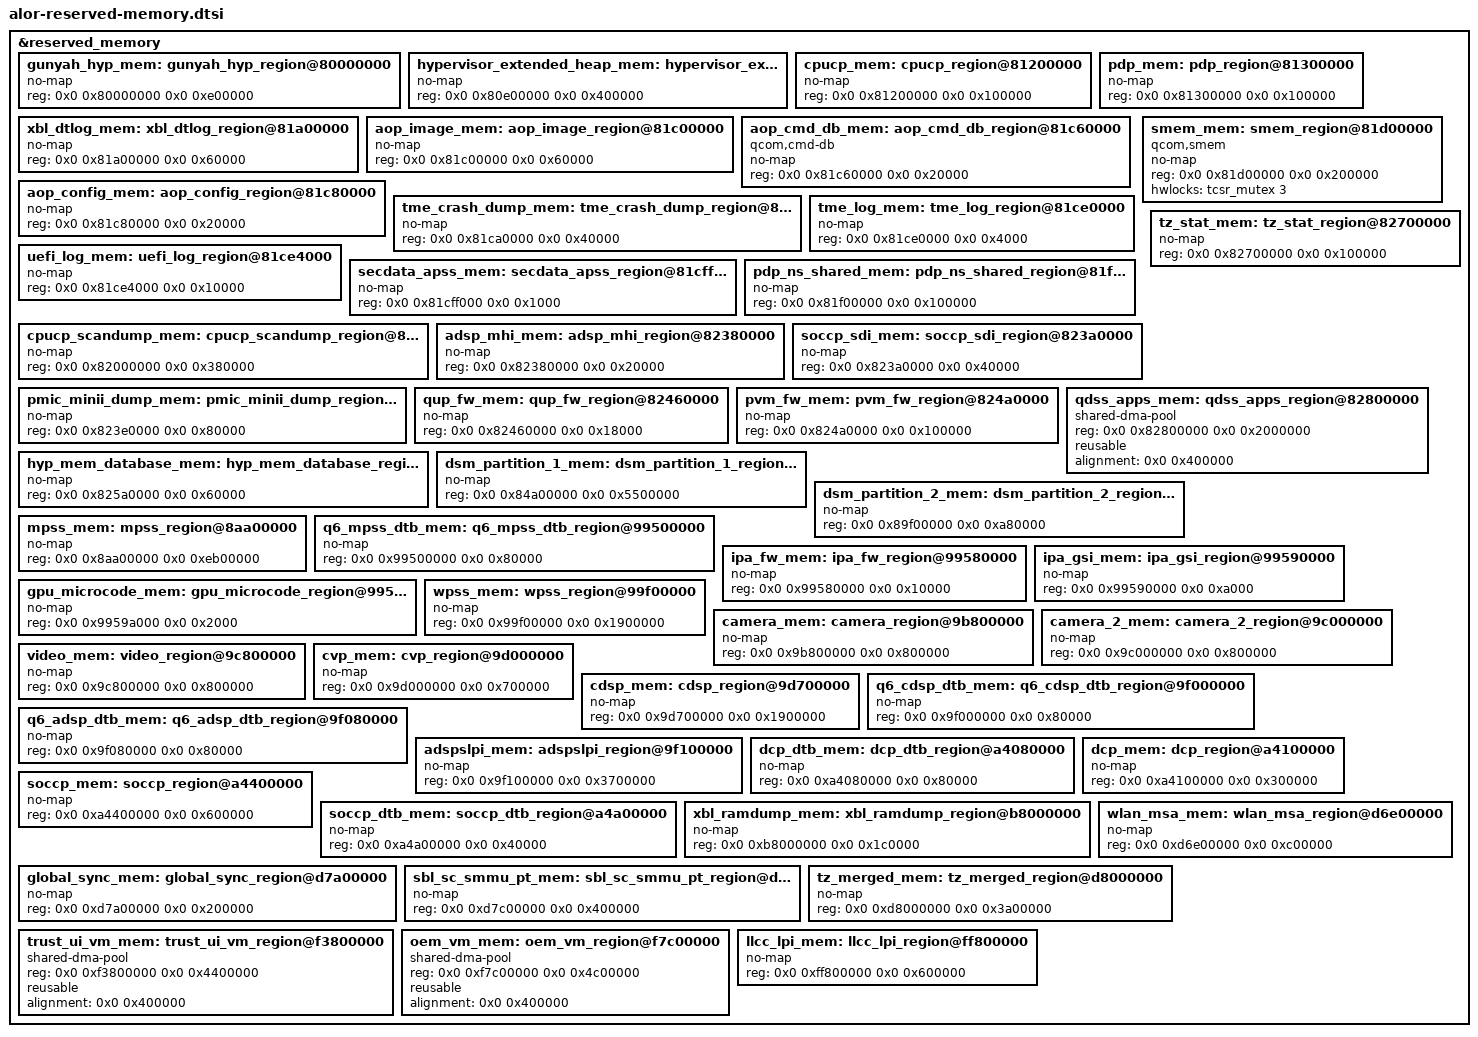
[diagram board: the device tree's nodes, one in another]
// SPDX-License-Identifier: BSD-3-Clause
/*
 * Copyright (c) Qualcomm Technologies, Inc. and/or its subsidiaries.
 */

&reserved_memory {
	#address-cells = <2>;
	#size-cells = <2>;
	ranges;

	gunyah_hyp_mem: gunyah_hyp_region@80000000 {
		no-map;
		reg = <0x0 0x80000000 0x0 0xe00000>;
	};

	hypervisor_extended_heap_mem: hypervisor_extended_heap_region@80e00000 {
		no-map;
		reg = <0x0 0x80e00000 0x0 0x400000>;
	};

	cpucp_mem: cpucp_region@81200000 {
		no-map;
		reg = <0x0 0x81200000 0x0 0x100000>;
	};

	pdp_mem: pdp_region@81300000 {
		no-map;
		reg = <0x0 0x81300000 0x0 0x100000>;
	};

	/*
	 * hyp_tags_mem is dynamically removed from the RAM
	 * partition tables before boot occurs. Size of region
	 * varies.
	 */

	xbl_dtlog_mem: xbl_dtlog_region@81a00000 {
		no-map;
		reg = <0x0 0x81a00000 0x0 0x60000>;
	};

	aop_image_mem: aop_image_region@81c00000 {
		no-map;
		reg = <0x0 0x81c00000 0x0 0x60000>;
	};

	aop_cmd_db_mem: aop_cmd_db_region@81c60000 {
		compatible = "qcom,cmd-db";
		no-map;
		reg = <0x0 0x81c60000 0x0 0x20000>;
	};

	aop_config_mem: aop_config_region@81c80000 {
		no-map;
		reg = <0x0 0x81c80000 0x0 0x20000>;
	};

	tme_crash_dump_mem: tme_crash_dump_region@81ca0000 {
		no-map;
		reg = <0x0 0x81ca0000 0x0 0x40000>;
	};

	tme_log_mem: tme_log_region@81ce0000 {
		no-map;
		reg = <0x0 0x81ce0000 0x0 0x4000>;
	};

	uefi_log_mem: uefi_log_region@81ce4000 {
		no-map;
		reg = <0x0 0x81ce4000 0x0 0x10000>;
	};

	secdata_apss_mem: secdata_apss_region@81cff000 {
		no-map;
		reg = <0x0 0x81cff000 0x0 0x1000>;
	};

	smem_mem: smem_region@81d00000 {
		compatible = "qcom,smem";
		no-map;
		reg = <0x0 0x81d00000 0x0 0x200000>;
		hwlocks = <&tcsr_mutex 3>;
	};

	pdp_ns_shared_mem: pdp_ns_shared_region@81f00000 {
		no-map;
		reg = <0x0 0x81f00000 0x0 0x100000>;
	};

	cpucp_scandump_mem: cpucp_scandump_region@82000000 {
		no-map;
		reg = <0x0 0x82000000 0x0 0x380000>;
	};

	adsp_mhi_mem: adsp_mhi_region@82380000 {
		no-map;
		reg = <0x0 0x82380000 0x0 0x20000>;
	};

	soccp_sdi_mem: soccp_sdi_region@823a0000 {
		no-map;
		reg = <0x0 0x823a0000 0x0 0x40000>;
	};

	pmic_minii_dump_mem: pmic_minii_dump_region@823e0000 {
		no-map;
		reg = <0x0 0x823e0000 0x0 0x80000>;
	};

	qup_fw_mem: qup_fw_region@82460000 {
		no-map;
		reg = <0x0 0x82460000 0x0 0x18000>;
	};

	pvm_fw_mem: pvm_fw_region@824a0000 {
		no-map;
		reg = <0x0 0x824a0000 0x0 0x100000>;
	};

	hyp_mem_database_mem: hyp_mem_database_region@825a0000 {
		no-map;
		reg = <0x0 0x825a0000 0x0 0x60000>;
	};

	tz_stat_mem: tz_stat_region@82700000 {
		no-map;
		reg = <0x0 0x82700000 0x0 0x100000>;
	};

	qdss_apps_mem: qdss_apps_region@82800000 {
		compatible = "shared-dma-pool";
		reg = <0x0 0x82800000 0x0 0x2000000>;
		reusable;
		alignment = <0x0 0x400000>;
	};

	dsm_partition_1_mem: dsm_partition_1_region@84a00000 {
		no-map;
		reg = <0x0 0x84a00000 0x0 0x5500000>;
	};

	dsm_partition_2_mem: dsm_partition_2_region@89f00000 {
		no-map;
		reg = <0x0 0x89f00000 0x0 0xa80000>;
	};

	mpss_mem: mpss_region@8aa00000 {
		no-map;
		reg = <0x0 0x8aa00000 0x0 0xeb00000>;
	};

	q6_mpss_dtb_mem: q6_mpss_dtb_region@99500000 {
		no-map;
		reg = <0x0 0x99500000 0x0 0x80000>;
	};

	ipa_fw_mem: ipa_fw_region@99580000 {
		no-map;
		reg = <0x0 0x99580000 0x0 0x10000>;
	};

	ipa_gsi_mem: ipa_gsi_region@99590000 {
		no-map;
		reg = <0x0 0x99590000 0x0 0xa000>;
	};

	gpu_microcode_mem: gpu_microcode_region@9959a000 {
		no-map;
		reg = <0x0 0x9959a000 0x0 0x2000>;
	};

	wpss_mem: wpss_region@99f00000 {
		no-map;
		reg = <0x0 0x99f00000 0x0 0x1900000>;
	};

	camera_mem: camera_region@9b800000 {
		no-map;
		reg = <0x0 0x9b800000 0x0 0x800000>;
	};

	camera_2_mem: camera_2_region@9c000000 {
		no-map;
		reg = <0x0 0x9c000000 0x0 0x800000>;
	};

	video_mem: video_region@9c800000 {
		no-map;
		reg = <0x0 0x9c800000 0x0 0x800000>;
	};

	cvp_mem: cvp_region@9d000000 {
		no-map;
		reg = <0x0 0x9d000000 0x0 0x700000>;
	};

	cdsp_mem: cdsp_region@9d700000 {
		no-map;
		reg = <0x0 0x9d700000 0x0 0x1900000>;
	};

	q6_cdsp_dtb_mem: q6_cdsp_dtb_region@9f000000 {
		no-map;
		reg = <0x0 0x9f000000 0x0 0x80000>;
	};

	q6_adsp_dtb_mem: q6_adsp_dtb_region@9f080000 {
		no-map;
		reg = <0x0 0x9f080000 0x0 0x80000>;
	};

	adspslpi_mem: adspslpi_region@9f100000 {
		no-map;
		reg = <0x0 0x9f100000 0x0 0x3700000>;
	};

	dcp_dtb_mem: dcp_dtb_region@a4080000 {
		no-map;
		reg = <0x0 0xa4080000 0x0 0x80000>;
	};

	dcp_mem: dcp_region@a4100000 {
		no-map;
		reg = <0x0 0xa4100000 0x0 0x300000>;
	};

	soccp_mem: soccp_region@a4400000 {
		no-map;
		reg = <0x0 0xa4400000 0x0 0x600000>;
	};

	soccp_dtb_mem: soccp_dtb_region@a4a00000 {
		no-map;
		reg = <0x0 0xa4a00000 0x0 0x40000>;
	};

	/* uefi region can be reused by apps */

	/* Linux kernel image is loaded at 0xa8000000 */

	xbl_ramdump_mem: xbl_ramdump_region@b8000000 {
		no-map;
		reg = <0x0 0xb8000000 0x0 0x1c0000>;
	};

	wlan_msa_mem: wlan_msa_region@d6e00000 {
		no-map;
		reg = <0x0 0xd6e00000 0x0 0xc00000>;
	};

	global_sync_mem: global_sync_region@d7a00000 {
		no-map;
		reg = <0x0 0xd7a00000 0x0 0x200000>;
	};

	sbl_sc_smmu_pt_mem: sbl_sc_smmu_pt_region@d7c00000 {
		no-map;
		reg = <0x0 0xd7c00000 0x0 0x400000>;
	};

	/* merged hyp_ac_config_mem, xbl_sc, tz_ac_config, tz_reserved, and qtee regions */
	tz_merged_mem: tz_merged_region@d8000000 {
		no-map;
		reg = <0x0 0xd8000000 0x0 0x3a00000>;
	};

	trust_ui_vm_mem: trust_ui_vm_region@f3800000 {
		compatible = "shared-dma-pool";
		reg = <0x0 0xf3800000 0x0 0x4400000>;
		reusable;
		alignment = <0x0 0x400000>;
	};

	oem_vm_mem: oem_vm_region@f7c00000 {
		compatible = "shared-dma-pool";
		reg = <0x0 0xf7c00000 0x0 0x4c00000>;
		reusable;
		alignment = <0x0 0x400000>;
	};

	llcc_lpi_mem: llcc_lpi_region@ff800000 {
		no-map;
		reg = <0x0 0xff800000 0x0 0x600000>;
	};
};
